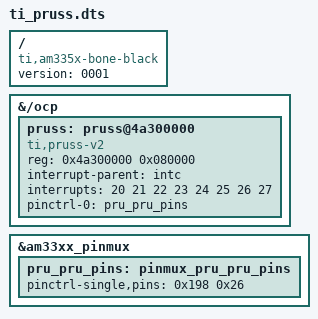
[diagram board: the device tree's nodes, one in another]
/dts-v1/;
/plugin/;

/{
  compatible = "ti,am335x-bone-black", "ti,am335x-bone", "ti,am33xx";
  version = "0001";

  fragment@0 {
      target-path = "/ocp";

      __overlay__ {
        pruss: pruss@4a300000 {
                   compatible = "ti,pruss-v2";
                   reg = <0x4a300000 0x080000>;
                   interrupt-parent = <&intc>;
                   interrupts = <20 21 22 23 24 25 26 27>;
                   status = "okay";
                   pinctrl-names = "default";
                   pinctrl-0 = <&pru_pru_pins>;
               };
      };
  };

  fragment@1 {
      target = <&am33xx_pinmux>;
      __overlay__ {

        pru_pru_pins: pinmux_pru_pru_pins {
                  pinctrl-single,pins = <
                      0x198 0x26	/* PRU0-2 */
                      >;
              };
      };
  };

};

